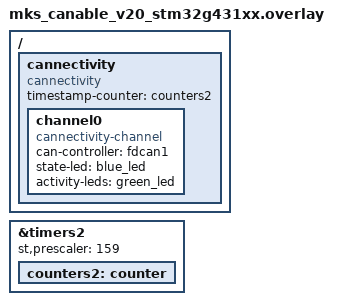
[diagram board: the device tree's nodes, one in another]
/*
 * Copyright (c) 2024 Alexander Kozhinov <ak.alexander.kozhinov@gmail.com>
 *
 * SPDX-License-Identifier: Apache-2.0
 */

#include <zephyr/dt-bindings/gpio/gpio.h>
#include "../app.overlay"

/ {
	cannectivity: cannectivity {
		compatible = "cannectivity";
		timestamp-counter = <&counters2>;

		channel0 {
			compatible = "cannectivity-channel";
			can-controller = <&fdcan1>;
			state-led = <&blue_led>;
			activity-leds = <&green_led>;
		};
	};
};

&timers2 {
	st,prescaler = <159>;
	counters2: counter {
		status = "okay";
	};
};
